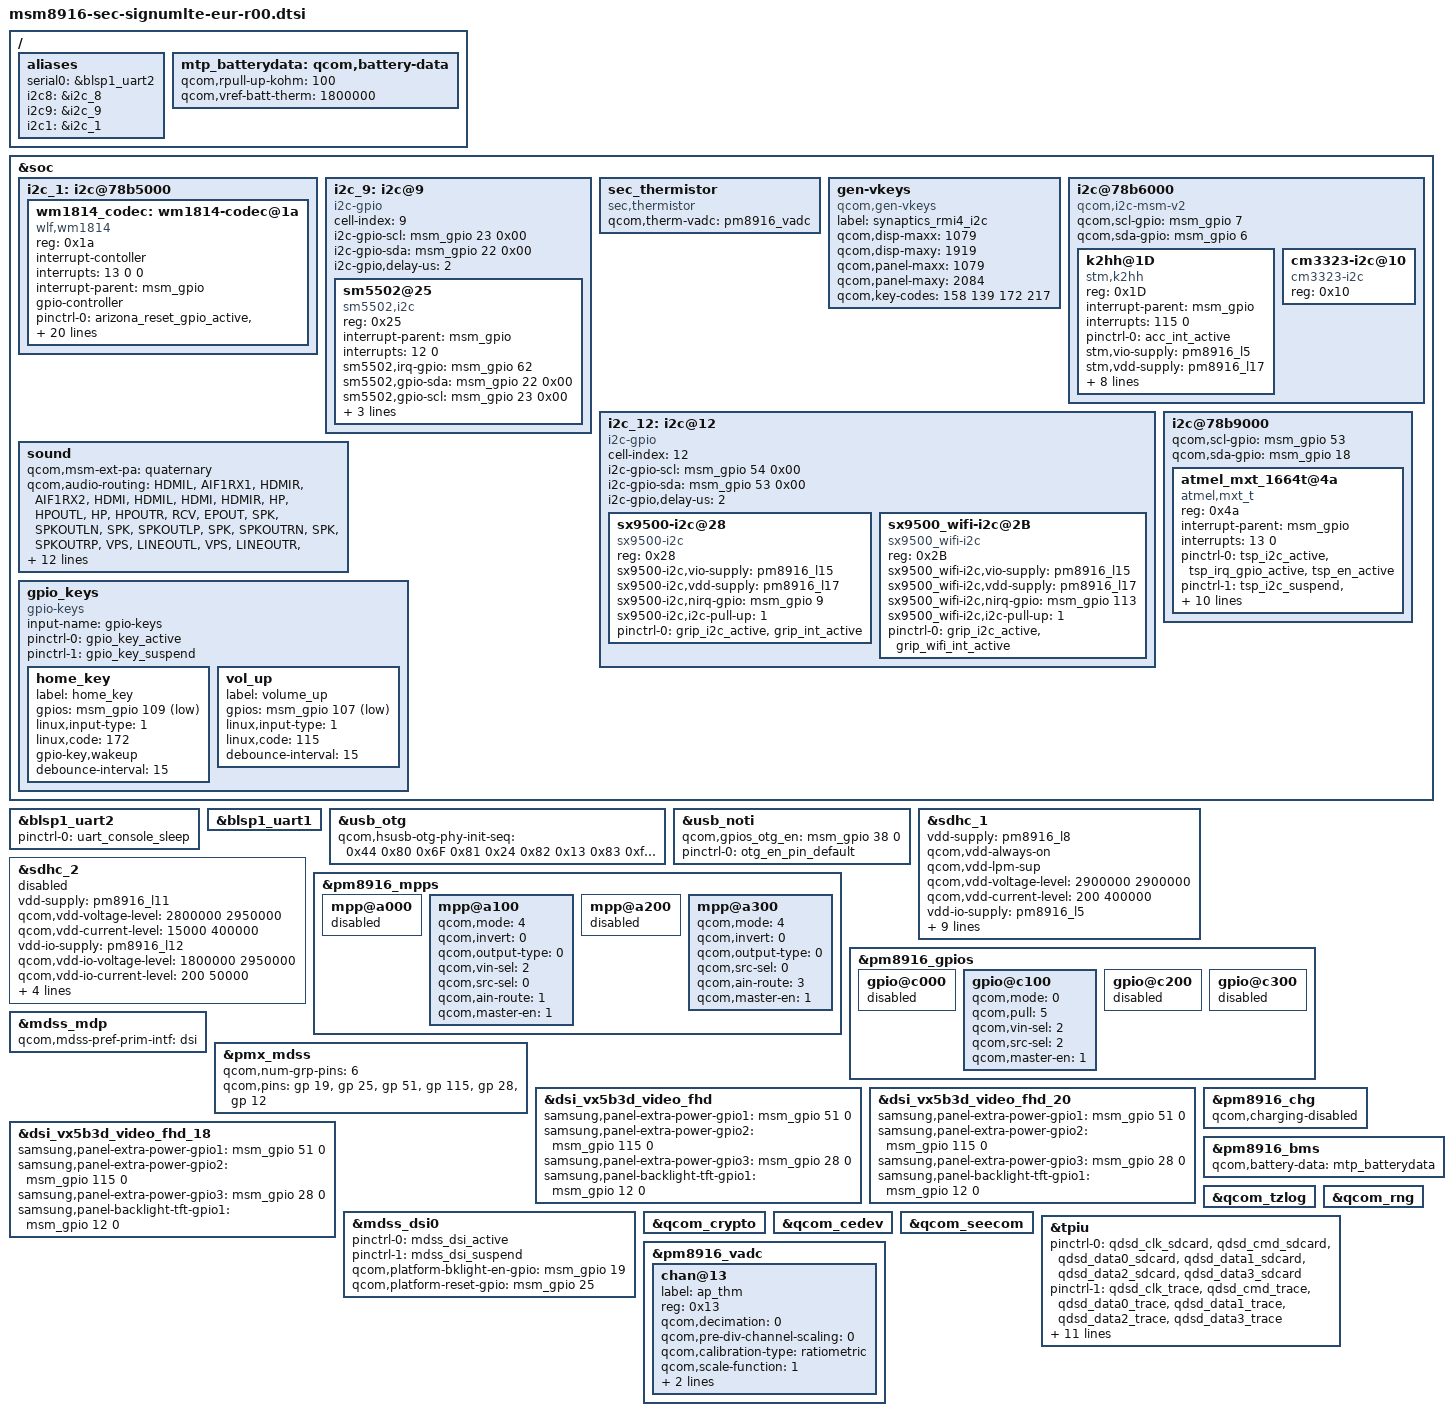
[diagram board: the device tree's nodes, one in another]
/* Copyright (c) 2014, The Linux Foundation. All rights reserved.
 *
 * This program is free software; you can redistribute it and/or modify
 * it under the terms of the GNU General Public License version 2 and
 * only version 2 as published by the Free Software Foundation.
 *
 * This program is distributed in the hope that it will be useful,
 * but WITHOUT ANY WARRANTY; without even the implied warranty of
 * MERCHANTABILITY or FITNESS FOR A PARTICULAR PURPOSE.  See the
 * GNU General Public License for more details.
 */

#include "msm8916.dtsi"
#include "msm8916-pinctrl-sec-signumlte-eur-r00.dtsi"
#include "msm8916-camera-sensor-signumlte.dtsi"
#include "../../../../../../drivers/video/msm/mdss/samsung/VX5B3D_LTI550HN06/dsi_panel_VX5B3D_LTI550HN06.dtsi"
#include "../../../../../../drivers/video/msm/mdss/samsung/VX5B3D_LTM215HT05/dsi_panel_VX5B3D_LTM215HT05.dtsi"
#include "../../../../../../drivers/video/msm/mdss/samsung/VX5B3D_LTM184HL01/dsi_panel_VX5B3D_LTM184HL01.dtsi"

/ {
	aliases {
		serial0 = &blsp1_uart2;
		i2c8 = &i2c_8;
		i2c9 = &i2c_9;
		i2c1 = &i2c_1;
	};
};

&soc {

	i2c_1: i2c@78b5000 { /* BLSP1 QUP1 */
		wm1814_codec: wm1814-codec@1a {
			compatible = "wlf,wm1814";
			reg = <0x1a>;

			interrupt-contoller;
			#interrupt-cells = <2>;
			interrupts = <13 0 0>;
			interrupt-parent = <&msm_gpio>;

			gpio-controller;
			#gpio-cells = <2>;

			pinctrl-names = "arizona_gpio_active",
					"arizona_gpio_suspend";
			pinctrl-0 = <&arizona_reset_gpio_active &arizona_ldo_gpio_active &arizona_codec_irq_n_active>;
			pinctrl-1 = <&arizona_reset_gpio_suspend &arizona_ldo_gpio_suspend &arizona_codec_irq_n_suspend>;

			wlf,reset = <&msm_gpio 31 0>;
			wlf,ldoena = <&msm_gpio 120 0>;

			wlf,gpio-defaults = <
				0xA101
				0xA101
				0xA101
				0xA101
				0x8101
			>;

			wlf,max-channels-clocked = <2 0 0>;
			/* 0:MICVDD 1:MICBIAS1 2:MICBIAS2 3:MICBIAS3 */
			wlf,dmic-ref = <2 1 3 0>;
			/* 1st cell:IN1 2rd cell:IN2 3nd cell:IN3 4th cell:IN4 */
			wlf,inmode = <0 0 0 0>;
			/* 1st cell:OUT1 2nd cell:OUT2 3rd cell:OUT3... 6th cell:OUT6 */
			wlf,out-mono = <0 1 1 0 0 0>;

			AVDD-supply = <&pm8916_l5>;
			CPVDD-supply = <&pm8916_l5>;
			DBVDD1-supply = <&pm8916_l5>;
			DBVDD2-supply = <&pm8916_l5>;
			DBVDD3-supply = <&pm8916_l5>;
			SPKVDDL-supply = <&pm8916_l5>;
			SPKVDDR-supply = <&pm8916_l5>;
		};
	};

	i2c_9:i2c@9 { /*SM5502 GPIO-I2C*/
		cell-index = <9>;
		compatible = "i2c-gpio";
		i2c-gpio-scl = <&msm_gpio 23 0x00>;
		i2c-gpio-sda = <&msm_gpio 22 0x00>;
		i2c-gpio,delay-us = <2>;
		#address-cells = <1>;
		#size-cells = <0>;

		sm5502@25{
			compatible = "sm5502,i2c";
			reg = <0x25>;
			interrupt-parent = <&msm_gpio>;
			interrupts= <12 0>;
			sm5502,irq-gpio = <&msm_gpio 62 0x00>;
			sm5502,gpio-sda = <&msm_gpio 22 0x00>;
			sm5502,gpio-scl = <&msm_gpio 23 0x00>;
			sm5502,uarton-gpio = <&msm_gpio 114 0x00>;
			pinctrl-names = "sm5502_i2c_active","sm5502_i2c_suspend";
			pinctrl-0 = <&muic_i2c_active &muic_int_pin>;
			pinctrl-1 = <&muic_i2c_suspend &muic_int_pin>;
		};
	};

	sec_thermistor {
		compatible = "sec,thermistor";
		qcom,therm-vadc = <&pm8916_vadc>;
	};

	gen-vkeys {
		compatible = "qcom,gen-vkeys";
		label = "synaptics_rmi4_i2c";
		qcom,disp-maxx = <1079>;
		qcom,disp-maxy = <1919>;
		qcom,panel-maxx = <1079>;
		qcom,panel-maxy = <2084>;
		qcom,key-codes = <158 139 172 217>;
	};

	i2c@78b6000 { /* BLSP1 QUP2 */
		compatible = "qcom,i2c-msm-v2";
		qcom,scl-gpio = <&msm_gpio 7 0>;
		qcom,sda-gpio = <&msm_gpio 6 0>;
		k2hh@1D {
			compatible = "stm,k2hh";
			reg = <0x1D>;
			interrupt-parent = <&msm_gpio>;
			interrupts = <115 0>;
			pinctrl-names = "default";
			pinctrl-0 = <&acc_int_active>;
/*			stm,irq_gpio = <&msm_gpio 115 0x00>;*/
			stm,vio-supply = <&pm8916_l5>;
			stm,vdd-supply = <&pm8916_l17>;
			stm,axis_map_x = <1>;
			stm,axis_map_y = <0>;
			stm,axis_map_z = <2>;
			stm,negate_x = <1>;
			stm,negate_y = <0>;
			stm,negate_z = <1>;
			stm,poll_interval = <100>;
			stm,min_interval = <2>;
		};
		cm3323-i2c@10 {
			compatible = "cm3323-i2c";
			reg = <0x10>;
		};
	};

	i2c_12:i2c@12 {
		cell-index = <12>;
		compatible = "i2c-gpio";
		i2c-gpio-scl = <&msm_gpio 54 0x00>;
		i2c-gpio-sda = <&msm_gpio 53 0x00>;
		i2c-gpio,delay-us = <2>;
		#address-cells = <1>;
		#size-cells = <0>;
		sx9500-i2c@28 {
			compatible = "sx9500-i2c";
			reg = <0x28>;
			sx9500-i2c,vio-supply = <&pm8916_l15>;
			sx9500-i2c,vdd-supply = <&pm8916_l17>;
			sx9500-i2c,nirq-gpio = <&msm_gpio 9 0x00>;
			sx9500-i2c,i2c-pull-up = <1>;
			pinctrl-names = "default";
			pinctrl-0 = <&grip_i2c_active &grip_int_active>;
		};
		sx9500_wifi-i2c@2B {
			compatible = "sx9500_wifi-i2c";
			reg = <0x2B>;
			sx9500_wifi-i2c,vio-supply = <&pm8916_l15>;
			sx9500_wifi-i2c,vdd-supply = <&pm8916_l17>;
			sx9500_wifi-i2c,nirq-gpio = <&msm_gpio 113 0x00>;
			sx9500_wifi-i2c,i2c-pull-up = <1>;
			pinctrl-names = "default";
			pinctrl-0 = <&grip_i2c_active &grip_wifi_int_active>;
		};
	};

	/* Over-riding model specific changes */
	sound {
		qcom,msm-ext-pa = "quaternary";
		qcom,audio-routing =
			 "HDMIL", "AIF1RX1",
			 "HDMIR", "AIF1RX2",
			 "HDMI", "HDMIL" ,
			 "HDMI", "HDMIR",
			 "HP", "HPOUTL",
			 "HP", "HPOUTR",
			 "RCV", "EPOUT",
			 "SPK", "SPKOUTLN",
			 "SPK", "SPKOUTLP",
			 "SPK", "SPKOUTRN",
			 "SPK", "SPKOUTRP",
			 "VPS", "LINEOUTL",
			 "VPS", "LINEOUTR",
			 /* SEL of main mic is connected to GND */
			 "Main Mic", "MICBIAS2",
			 "IN1BL", "Main Mic",
			/* Sub mic is Analog Mic */
			 "IN1BR", "Sub Mic",
			/* Headset mic is Analog Mic */
			 "Headset Mic", "MICBIAS1",
			 "IN2B", "Headset Mic";
		pinctrl-names = "cdc_lines_act",
				"cdc_lines_sus",
				"cdc_lines_quat_ext_act",
				"cdc_lines_quat_ext_sus";
		pinctrl-0 = <&cdc_pdm_lines_act>;
		pinctrl-1 = <&cdc_pdm_lines_sus>;
		pinctrl-2 = <&cdc_pdm_lines_act &ext_cdc_tlmm_lines_act>;
		pinctrl-3 = <&cdc_pdm_lines_sus &ext_cdc_tlmm_lines_sus>;
		asoc-codec = <&stub_codec>, <&wm1814_codec>;
		asoc-codec-names = "msm-stub-codec.1", "wm8998-codec";
	};
};

&blsp1_uart2 {
	status = "ok";
	pinctrl-names = "default";
	pinctrl-0 = <&uart_console_sleep>;
};

&soc {
	gpio_keys {
		compatible = "gpio-keys";
		input-name = "gpio-keys";
		pinctrl-names = "tlmm_gpio_key_active","tlmm_gpio_key_suspend";
		pinctrl-0 = <&gpio_key_active>;
		pinctrl-1 = <&gpio_key_suspend>;

		home_key {
			label = "home_key";
			gpios = <&msm_gpio 109 0x1>;
			linux,input-type = <1>;
			linux,code = <172>;
			gpio-key,wakeup;
			debounce-interval = <15>;
		};

		vol_up {
			label = "volume_up";
			gpios = <&msm_gpio 107 0x1>;
			linux,input-type = <1>;
			linux,code = <115>;
			debounce-interval = <15>;
		};
	};

/*	i2c_10:i2c@10 {
		cell-index = <10>;
		compatible = "i2c-gpio";
		i2c-gpio-scl = <&msm_gpio 17  0x00>;
		i2c-gpio-sda = <&msm_gpio 16 0x00>;
		i2c-gpio,delay-us = <1>;
		#address-cells = <1>;
		#size-cells = <0>;

		tc360@20 {
			compatible = "coreriver,coreriver-tkey";
			reg = <0x20>;
			interrupt-parent = <&msm_gpio>;
			interrupts = <98 0>;
			pinctrl-names = "tkey_gpio_active","tkey_gpio_suspend";
			pinctrl-0 = <&tkey_i2c_active>;
			pinctrl-1 = <&tkey_i2c_active>;

			//coreriver,vcc_en_ldo_name = "max77826_ldo15";
			coreriver,vcc_en-gpio = <&msm_gpio 97 0x00>;
			//coreriver,vdd_led_ldo_name = "max77826_ldo12";
			coreriver,scl-gpio = <&msm_gpio 17 0x00>;
			coreriver,sda-gpio = <&msm_gpio 16 0x00>;
			coreriver,irq-gpio = <&msm_gpio  98 0x00>;
			coreriver,tkey-keycodes = <254 158>;
			coreriver,i2c-pull-up = <1>;
			coreriver,gpio_seperated = <1>;
			//coreriver,firm-up;

		};
	};*/

      i2c@78b9000 { /* BLSP1 QUP5 */
		qcom,scl-gpio = <&msm_gpio 53 0>;
		qcom,sda-gpio = <&msm_gpio 18 0>;
                status = "okay";
			atmel_mxt_1664t@4a {
				compatible = "atmel,mxt_t";
				reg = <0x4a>;
				interrupt-parent = <&msm_gpio>;
				interrupts = <13 0>;
				pinctrl-names = "tsp_gpio_active", "tsp_gpio_suspend";
				pinctrl-0 = <&tsp_i2c_active &tsp_irq_gpio_active &tsp_en_active >;
				pinctrl-1 = <&tsp_i2c_suspend &tsp_irq_gpio_suspend &tsp_en_suspend>;
				mxts,scl-gpio = <&msm_gpio 53 0x00>;
				mxts,sda-gpio = <&msm_gpio 18 0x00>;
				mxts,external_ldo = <&msm_gpio 73 0x01>; /*Touch En 1 gpio*/
				mxts,irq-gpio = <&msm_gpio 13 0x00>;
				vcc_en-supply = <&pm8916_l5>;
				mxts,rst = <&msm_gpio 114 0x1>;
				mxts,i2c-pull-up = <1>;
				mxts,tsp_coord = <31 45 767 1023>;
				mxts,pname = "GT510";
		};
	};

};

&blsp1_uart1 {
	status = "ok";
};

&usb_otg {
	qcom,hsusb-otg-phy-init-seq =
					<0x44 0x80 0x6F 0x81 0x24 0x82 0x13 0x83 0xffffffff>;
};

&usb_noti {
	qcom,gpios_otg_en = <&msm_gpio 38 0>;
	pinctrl-names = "default";
	pinctrl-0 = <&otg_en_pin_default>;
	status = "ok";
};

&sdhc_1 {
	vdd-supply = <&pm8916_l8>;
	qcom,vdd-always-on;
	qcom,vdd-lpm-sup;
	qcom,vdd-voltage-level = <2900000 2900000>;
	qcom,vdd-current-level = <200 400000>;

	vdd-io-supply = <&pm8916_l5>;
	qcom,vdd-io-always-on;
	qcom,vdd-io-lpm-sup;
	qcom,vdd-io-voltage-level = <1800000 1800000>;
	qcom,vdd-io-current-level = <200 60000>;

	pinctrl-names = "active", "sleep";
	pinctrl-0 = <&sdc1_clk_on &sdc1_cmd_on &sdc1_data_on>;
	pinctrl-1 = <&sdc1_clk_off &sdc1_cmd_off &sdc1_data_off>;

	qcom,nonremovable;

	status = "ok";
};

&sdhc_2 {
	vdd-supply = <&pm8916_l11>;
	qcom,vdd-voltage-level = <2800000 2950000>;
	qcom,vdd-current-level = <15000 400000>;

	vdd-io-supply = <&pm8916_l12>;
	qcom,vdd-io-voltage-level = <1800000 2950000>;
	qcom,vdd-io-current-level = <200 50000>;

	pinctrl-names = "active", "sleep";
	pinctrl-0 = <&sdc2_clk_on &sdc2_cmd_on &sdc2_data_on &sdc2_cd_on>;
	pinctrl-1 = <&sdc2_clk_off &sdc2_cmd_off &sdc2_data_off &sdc2_cd_off>;


	/* #address-cells = <0>;
	interrupt-parent = <&sdhc_2>;
	interrupts = <0 1 2>;
	#interrupt-cells = <1>;
	interrupt-map-mask = <0xffffffff>;
	interrupt-map = <0 &intc 0 125 0
			1 &intc 0 221 0
			2 &msm_gpio 38 0>;
	interrupt-names = "hc_irq", "pwr_irq", "status_irq";
	cd-gpios = <&msm_gpio 38 0x1>; */

	status = "disabled";
};

&pm8916_mpps {
	mpp@a000 { /* MPP 1 */
		/* VDD_PX */
		status = "disabled";
	};

	mpp@a100 { /* MPP 2 */
		status = "ok";
		qcom,mode = <4>; // AIN input
		qcom,invert = <0>; //No Invert
		qcom,output-type = <0>; //CMOS
		qcom,vin-sel = <2>; //PM8971_S3 1.8v
		qcom,src-sel = <0>; //MPP Constant
		qcom,ain-route = <1>; // QPNP_PIN_AIN_AMUX_CH6 = 1 for MPP2
		qcom,master-en = <1>; // Function constant
	};

	mpp@a200 { /* MPP 3 */
		/* VREF DAC */
		status = "disabled";
	};

	mpp@a300 { /* MPP 4 */
		status = "ok";
		qcom,mode = <4>;		/* AIN Input */
		qcom,invert = <0>;		/* Disable invert */
		qcom,output-type = <0>;		/* CMOS */
		qcom,src-sel = <0>;		/* /MPP Constant */
		qcom,ain-route = <3>;		/* QPNP_PIN_AIN_AMUX_CH8 = 3 for MPP4 */
		qcom,master-en = <1>;		/* Enable MPP */
	};
};

&pm8916_gpios {
	gpio@c000 { /* GPIO 1 */
		/* Battery UICC Alarm */
		status = "disabled";
	};

	gpio@c100 { /* GPIO 2 */
		/* NFC_CLK_REQ */
		qcom,mode = <0>; /* QPNP_PIN_MODE_DIG_IN */
		qcom,pull = <5>; /* QPNP_PIN_PULL_NO */
		qcom,vin-sel = <2>; /* QPNP_PIN_VIN2 */
		qcom,src-sel = <2>; /* QPNP_PIN_SEL_FUNC_1 */
		qcom,master-en = <1>;
	};

	gpio@c200 { /* GPIO 3 */
		/* External regulator control for WTR */
		status = "disabled";
	};

	gpio@c300 { /* GPIO 4 */
		/* External regulator control for APC */
		status = "disabled";
	};
};

&mdss_mdp {
	qcom,mdss-pref-prim-intf = "dsi";
};

&pmx_mdss {
	qcom,num-grp-pins = <6>;
	qcom,pins = <&gp 19>, <&gp 25>, <&gp 51>,<&gp 115>, <&gp 28>, <&gp 12>;
 };

&dsi_vx5b3d_video_fhd{
	samsung,panel-extra-power-gpio1 = <&msm_gpio 51 0>;/*lvds on 3.3V*/
	samsung,panel-extra-power-gpio2 = <&msm_gpio 115 0>;/*lvds clk*/
	samsung,panel-extra-power-gpio3 = <&msm_gpio 28 0>;/*smp power*/
	samsung,panel-backlight-tft-gpio1 = <&msm_gpio 12 0>;/*for lvds sel: normal standard*/
};

&dsi_vx5b3d_video_fhd_20{
	samsung,panel-extra-power-gpio1 = <&msm_gpio 51 0>;/*lvds on 3.3V*/
	samsung,panel-extra-power-gpio2 = <&msm_gpio 115 0>;/*lvds clk*/
	samsung,panel-extra-power-gpio3 = <&msm_gpio 28 0>;/*smp power*/
	samsung,panel-backlight-tft-gpio1 = <&msm_gpio 12 0>;/*for lvds sel: normal standard*/
};

&dsi_vx5b3d_video_fhd_18{
	samsung,panel-extra-power-gpio1 = <&msm_gpio 51 0>;/*lvds on 3.3V*/
	samsung,panel-extra-power-gpio2 = <&msm_gpio 115 0>;/*lvds clk*/
	samsung,panel-extra-power-gpio3 = <&msm_gpio 28 0>;/*smp power*/
	samsung,panel-backlight-tft-gpio1 = <&msm_gpio 12 0>;/*for lvds sel: normal standard*/
};

&mdss_dsi0 {
	pinctrl-names = "mdss_default", "mdss_sleep";
	pinctrl-0 = <&mdss_dsi_active>;
	pinctrl-1 = <&mdss_dsi_suspend >;
	qcom,platform-bklight-en-gpio = <&msm_gpio 19 0>; /*lcd blic on*/
	qcom,platform-reset-gpio = <&msm_gpio 25 0>;
};

&pm8916_chg {
	status = "ok";
	qcom,charging-disabled;
};

/ {
	mtp_batterydata: qcom,battery-data {
		qcom,rpull-up-kohm = <100>;
		qcom,vref-batt-therm = <1800000>;

		#include "batterydata-palladium.dtsi"
	};
};

&pm8916_bms {
	status = "ok";
	qcom,battery-data = <&mtp_batterydata>;
};

&qcom_tzlog {
	status = "okay";
};

&qcom_rng {
	status = "okay";
};

&qcom_crypto {
	status = "okay";
};

&qcom_cedev {
	status = "okay";
};

&qcom_seecom {
	status = "okay";
};

/* CoreSight */
&tpiu {
      pinctrl-names = "sdcard", "trace", "swduart",
		      "swdtrc", "jtag", "spmi";
       /* NIDnT */
      pinctrl-0 = <&qdsd_clk_sdcard &qdsd_cmd_sdcard
                  &qdsd_data0_sdcard &qdsd_data1_sdcard
                  &qdsd_data2_sdcard &qdsd_data3_sdcard>;
      pinctrl-1 = <&qdsd_clk_trace &qdsd_cmd_trace
                  &qdsd_data0_trace &qdsd_data1_trace
                  &qdsd_data2_trace &qdsd_data3_trace>;
      pinctrl-2 = <&qdsd_cmd_swduart &qdsd_data0_swduart
                  &qdsd_data1_swduart &qdsd_data2_swduart
                  &qdsd_data3_swduart>;
      pinctrl-3 = <&qdsd_clk_swdtrc &qdsd_cmd_swdtrc
                  &qdsd_data0_swdtrc &qdsd_data1_swdtrc
                  &qdsd_data2_swdtrc &qdsd_data3_swdtrc>;
      pinctrl-4 = <&qdsd_cmd_jtag &qdsd_data0_jtag
                  &qdsd_data1_jtag &qdsd_data2_jtag
                  &qdsd_data3_jtag>;
      pinctrl-5 = <&qdsd_clk_spmi &qdsd_cmd_spmi
                  &qdsd_data0_spmi &qdsd_data3_spmi>;
};

&pm8916_vadc {
	chan@13 {
		label = "ap_thm";
		reg = <0x13>;	/* channel 19 for MPP4 , 1:1scale */
		qcom,decimation = <0>;
		qcom,pre-div-channel-scaling = <0>;	/* 1:1scale */
		qcom,calibration-type = "ratiometric";
		qcom,scale-function = <1>;
		qcom,hw-settle-time = <2>;
		qcom,fast-avg-setup = <0>;
	};
};
